# ATtiny441 device description
Architecture: AVR8; Family: tinyAVR
Registers are 8-bit, access not given, no defined reset value unless marked. A register's access mark holds for its fields unless they carry their own. Offsets are from the block's base; [hi:lo] are bit positions.

## EEPROM
Instances: EEPROM 0x00
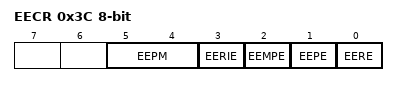
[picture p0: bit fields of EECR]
0x3C EECR — EEPROM Control Register
  [5:4] EEPM — EEPROM Programming Mode Bits
    0=Erase and Write in one operation; 1=Erase Only; 2=Write Only
  [3] EERIE — EEPROM Ready Interrupt Enable
  [2] EEMPE — EEPROM Master Write Enable
  [1] EEPE — EEPROM Write Enable
  [0] EERE — EEPROM Read Enable
0x3D EEDR — EEPROM Data Register
0x3E EEAR 16-bit bits used 8:0 — EEPROM Address Register Bytes

## TC1 (TC16 module) — Timer/Counter, 16-bit
Instances: TC1 0x00
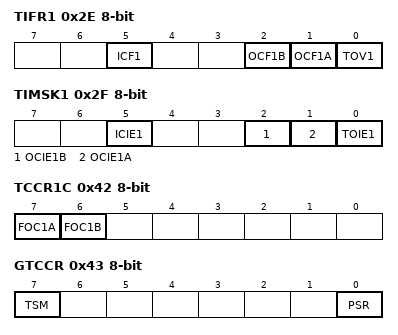
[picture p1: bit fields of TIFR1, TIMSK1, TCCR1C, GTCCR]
0x2E TIFR1 — Timer/Counter Interrupt Flag register
  [5] ICF1 — Timer/Counter1 Input Capture Flag
  [2] OCF1B — Timer/Counter1 Output Compare B Match Flag
  [1] OCF1A — Timer/Counter1 Output Compare A Match Flag
  [0] TOV1 — Timer/Counter1 Overflow Flag
0x2F TIMSK1 — Timer/Counter1 Interrupt Mask Register
  [5] ICIE1 — Timer/Counter1 Input Capture Interrupt Enable
  [2] OCIE1B — Timer/Counter1 Output Compare B Match Interrupt Enable
  [1] OCIE1A — Timer/Counter1 Output Compare A Match Interrupt Enable
  [0] TOIE1 — Timer/Counter1 Overflow Interrupt Enable
0x42 TCCR1C — Timer/Counter1 Control Register C
  [7] FOC1A — Force Output Compare for Channel A
  [6] FOC1B — Force Output Compare for Channel B
0x43 GTCCR — General Timer/Counter Control Register
  [7] TSM — Timer/Counter Synchronization Mode
  [0] PSR — Prescaler Reset Timer/CounterN
0x44 ICR1 16-bit — Timer/Counter1 Input Capture Register Bytes
0x48 OCR1B 16-bit — Timer/Counter1 Output Compare Register B Bytes
0x4A OCR1A 16-bit — Timer/Counter1 Output Compare Register A Bytes
0x4C TCNT1 16-bit — Timer/Counter1 Bytes
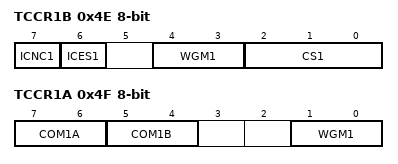
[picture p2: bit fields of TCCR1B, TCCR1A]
0x4E TCCR1B — Timer/Counter1 Control Register B
  [7] ICNC1 — Input Capture 1 Noise Canceler
  [6] ICES1 — Input Capture 1 Edge Select
  [4:3] WGM1 (bit 2 of the value upward) — Waveform Generation Mode Bits
  [2:0] CS1 — Clock Select bits
    0=No Clock Source (Stopped); 1=Running, No Prescaling; 2=Running, CLK/8; 3=Running, CLK/64; 4=Running, CLK/256; 5=Running, CLK/1024; 6=Running, ExtClk Tx Falling Edge; 7=Running, ExtClk Tx Rising Edge
0x4F TCCR1A — Timer/Counter1 Control Register A
  [7:6] COM1A — Compare Output Mode 1A, bits
  [5:4] COM1B — Compare Output Mode 1B, bits
  [1:0] WGM1 — Pulse Width Modulator Select Bits

## TC2 (TC8_ASYNC module) — Timer/Counter, 8-bit Async
Instances: TC2 0x00
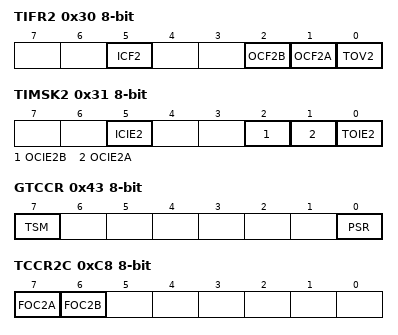
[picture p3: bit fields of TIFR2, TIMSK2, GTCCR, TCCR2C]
0x30 TIFR2 — Timer/Counter Interrupt Flag register
  [5] ICF2 — Timer/Counter2 Input Capture Flag
  [2] OCF2B — Timer/Counter2 Output Compare B Match Flag
  [1] OCF2A — Timer/Counter2 Output Compare A Match Flag
  [0] TOV2 — Timer/Counter2 Overflow Flag
0x31 TIMSK2 — Timer/Counter2 Interrupt Mask Register
  [5] ICIE2 — Timer/Counter2 Input Capture Interrupt Enable
  [2] OCIE2B — Timer/Counter2 Output Compare B Match Interrupt Enable
  [1] OCIE2A — Timer/Counter2 Output Compare A Match Interrupt Enable
  [0] TOIE2 — Timer/Counter2 Overflow Interrupt Enable
0x43 GTCCR — General Timer/Counter Control Register
  [7] TSM — Timer/Counter Synchronization Mode
  [0] PSR — Prescaler Reset Timer/CounterN
0xC0 ICR2 16-bit — Timer/Counter2 Input Capture Register Bytes
0xC2 OCR2B 16-bit — Timer/Counter2 Output Compare Register B Bytes
0xC4 OCR2A 16-bit — Timer/Counter2 Output Compare Register A Bytes
0xC6 TCNT2 16-bit — Timer/Counter2 Bytes
0xC8 TCCR2C — Timer/Counter2 Control Register C
  [7] FOC2A — Force Output Compare for Channel A
  [6] FOC2B — Force Output Compare for Channel B
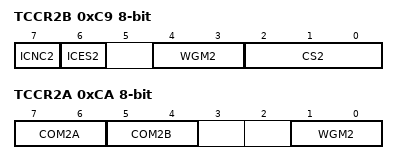
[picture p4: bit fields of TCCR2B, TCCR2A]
0xC9 TCCR2B — Timer/Counter2 Control Register B
  [7] ICNC2 — Input Capture 2 Noise Canceler
  [6] ICES2 — Input Capture 2 Edge Select
  [4:3] WGM2 (bit 2 of the value upward) — Waveform Generation Mode Bits
  [2:0] CS2 — Clock Select bits
    0=No Clock Source (Stopped); 1=Running, No Prescaling; 2=Running, CLK/8; 3=Running, CLK/64; 4=Running, CLK/256; 5=Running, CLK/1024; 6=Running, ExtClk Tx Falling Edge; 7=Running, ExtClk Tx Rising Edge
0xCA TCCR2A — Timer/Counter2 Control Register A
  [7:6] COM2A — Compare Output Mode 2A, bits
  [5:4] COM2B — Compare Output Mode 2B, bits
  [1:0] WGM2 — Pulse Width Modulator Select Bits
